# PIC16F722A register map
Vendor: Microchip
Architecture 16xxxx. Special function registers and configuration words.
Registers are 8-bit, read-write, reset 0x0 unless marked. A register's access mark holds for its fields unless they carry their own. Addresses are absolute, and some are shared; only a register's first bit layout is shown; lines under a group give offsets from that group; [hi:lo] are bit positions; {n}, {i} and the like mark numbered series; 'fields as' and 'values as' point back to an identical list; <NAME> marks a mode.

## Further device data
pins=1: RE3/MCLR/Vpp; 2: RA0/AN0/SS/Vcap; 3: RA1/AN1; 4: RA2/AN2; 5: RA3/AN3/Vref; 6: RA4/CPS6/T0CKI; 7: RA5/AN4/CPS7/SS/Vcap; 8: Vss; 9: RA7/OSC1/CLKIN; 10: RA6/OSC2/CLKOUT/Vcap; 11: RC0/T1OSO/T1CKI; 12: RC1/T1OSI/CCP2; 13: RC2/CCP1; 14: RC3/SCK/SCL; 15: RC4/SDI/SDA; 16: RC5/SDO; 17: RC6/TX/CK; 18: RC7/RX/DT; 19: Vss; 20: Vdd; 21: RB0/AN12/CPS0/INT; 22: RB1/AN10/CPS1; 23: RB2/AN8/CPS2; 24: RB3/AN9/CPS3/CCP2; 25: RB4/AN11/CPS4; 26: RB5/AN13/CPS5/T1G; 27: RB6/ICSPCLK/ICDCLK; 28: RB7/ICSPDAT/ICDDAT

## SFR
0x00 INDF access not given
0x01 TMR0 reset not defined — (power-on value xxxxxxxx)
0x02 PCL
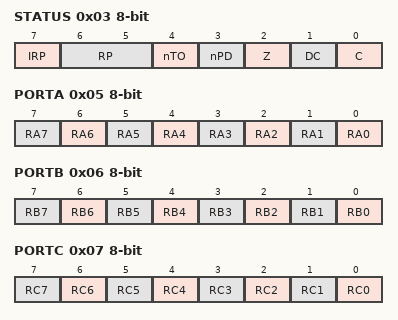
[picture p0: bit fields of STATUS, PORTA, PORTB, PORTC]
0x03 STATUS reset not defined — (power-on value 00011xxx)
  [7] IRP, [6:5] RP, [4] nTO ro, [3] nPD ro, [2] Z, [1] DC, [0] C
0x04 FSR reset not defined — (power-on value xxxxxxxx)
0x05 PORTA
  [n] RA{n} (n=0..7)
0x06 PORTB reset not defined — (power-on value xxxxxxxx)
  [n] RB{n} (n=0..7)
0x07 PORTC reset not defined — (power-on value xxxxxxxx)
  [n] RC{n} (n=0..7)
0x09 PORTE ro reset not defined — (power-on value ----x---)
  [3] RE3
0x0A PCLATH
  [4:0] PCLATH
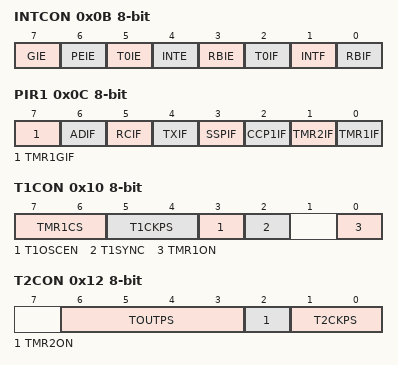
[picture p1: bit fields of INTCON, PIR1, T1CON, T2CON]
0x0B INTCON reset not defined — (power-on value 0000000x)
  [7] GIE, [6] PEIE, [5] T0IE, [4] INTE, [3] RBIE, [2] T0IF, [1] INTF, [0] RBIF
0x0C PIR1
  [7] TMR1GIF, [6] ADIF, [5] RCIF ro, [4] TXIF ro, [3] SSPIF, [2] CCP1IF, [1] TMR2IF, [0] TMR1IF
0x0D PIR2
  [0] CCP2IF
0x0E TMR1L reset not defined — (power-on value xxxxxxxx)
0x0F TMR1H reset not defined — (power-on value xxxxxxxx)
0x10 T1CON
  [7:6] TMR1CS, [5:4] T1CKPS, [3] T1OSCEN, [2] T1SYNC, [0] TMR1ON
0x11 TMR2
0x12 T2CON
  [6:3] TOUTPS, [2] TMR2ON, [1:0] T2CKPS
0x13 SSPBUF reset not defined — (power-on value xxxxxxxx)
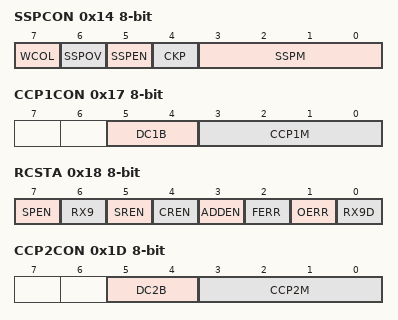
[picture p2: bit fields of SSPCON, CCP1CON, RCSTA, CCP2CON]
0x14 SSPCON
  [7] WCOL, [6] SSPOV, [5] SSPEN, [4] CKP, [3:0] SSPM
0x15 CCPR1L reset not defined — (power-on value xxxxxxxx)
0x16 CCPR1H reset not defined — (power-on value xxxxxxxx)
0x17 CCP1CON
  [5:4] DC1B, [3:0] CCP1M
0x18 RCSTA reset not defined — (power-on value 0000000x)
  [7] SPEN, [6] RX9, [5] SREN, [4] CREN, [3] ADDEN, [2] FERR ro, [1] OERR ro, [0] RX9D ro
0x19 TXREG
0x1A RCREG ro
0x1B CCPR2L reset not defined — (power-on value xxxxxxxx)
0x1C CCPR2H reset not defined — (power-on value xxxxxxxx)
0x1D CCP2CON
  [5:4] DC2B, [3:0] CCP2M
0x1E ADRES reset not defined — (power-on value xxxxxxxx)
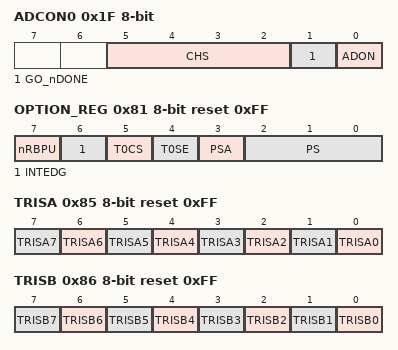
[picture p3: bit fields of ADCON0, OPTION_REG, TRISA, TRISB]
0x1F ADCON0
  [5:2] CHS, [1] GO_nDONE, [0] ADON
0x81 OPTION_REG reset 0xFF
  [7] nRBPU, [6] INTEDG, [5] T0CS, [4] T0SE, [3] PSA, [2:0] PS
0x85 TRISA reset 0xFF
  [n] TRISA{n} (n=0..7)
0x86 TRISB reset 0xFF
  [n] TRISB{n} (n=0..7)
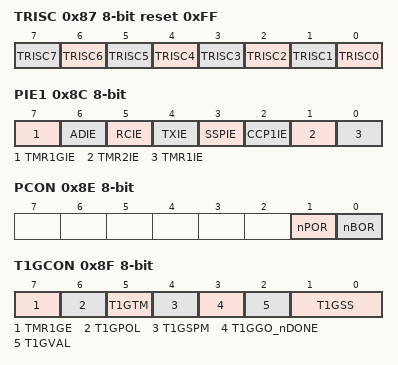
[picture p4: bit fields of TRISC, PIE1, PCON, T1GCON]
0x87 TRISC reset 0xFF
  [n] TRISC{n} (n=0..7)
0x89 TRISE ro reset 0x8
  [3] TRISE3
0x8C PIE1
  [7] TMR1GIE, [6] ADIE, [5] RCIE, [4] TXIE, [3] SSPIE, [2] CCP1IE, [1] TMR2IE, [0] TMR1IE
0x8D PIE2
  [0] CCP2IE
0x8E PCON reset not defined — (power-on value ------qq)
  [1] nPOR, [0] nBOR
0x8F T1GCON
  [7] TMR1GE, [6] T1GPOL, [5] T1GTM, [4] T1GSPM, [3] T1GGO_nDONE, [2] T1GVAL ro, [1:0] T1GSS
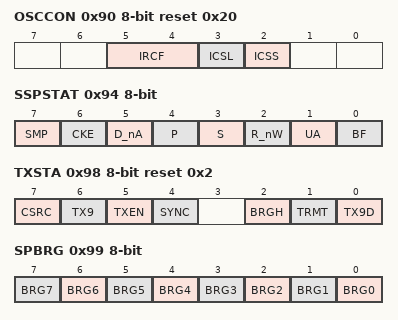
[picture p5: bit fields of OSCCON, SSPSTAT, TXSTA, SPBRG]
0x90 OSCCON reset 0x20
  [5:4] IRCF, [3] ICSL, [2] ICSS
0x91 OSCTUNE
  [5:0] TUN
0x92 PR2 reset 0xFF
0x93 SSPADD
0x93 SSPMSK reset 0xFF
0x94 SSPSTAT
  [7] SMP, [6] CKE, [5] D_nA, [4] P, [3] S, [2] R_nW, [1] UA, [0] BF
0x95 WPUB reset 0xFF
0x96 IOCB
0x98 TXSTA reset 0x2
  [7] CSRC, [6] TX9, [5] TXEN, [4] SYNC, [2] BRGH, [1] TRMT ro, [0] TX9D
0x99 SPBRG
  [n] BRG{n} (n=0..7)
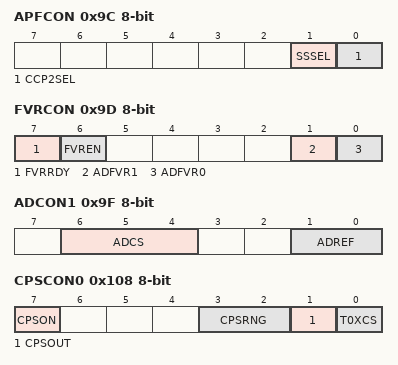
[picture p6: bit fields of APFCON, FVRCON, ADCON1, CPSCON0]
0x9C APFCON
  [1] SSSEL, [0] CCP2SEL
0x9D FVRCON reset not defined — (power-on value x0----00)
  [7] FVRRDY ro, [6] FVREN, [1] ADFVR1, [0] ADFVR0
0x9F ADCON1
  [6:4] ADCS, [1:0] ADREF
0x108 CPSCON0
  [7] CPSON, [3:2] CPSRNG, [1] CPSOUT ro, [0] T0XCS
0x109 CPSCON1
  [3:0] CPSCH
0x10C PMDATL reset not defined — (power-on value xxxxxxxx)
0x10D PMADRL reset not defined — (power-on value xxxxxxxx)
0x10E PMDATH reset not defined — (power-on value --xxxxxx)
  [5:0] PMDATH
0x10F PMADRH reset not defined — (power-on value ---xxxxx)
  [4:0] PMADRH
0x185 ANSELA reset 0x3F
  [5:0] ANSA
0x186 ANSELB reset 0x3F
  [5:0] ANSB
0x18C PMCON1 reset 0x80
  [0] RD

## CONFIG — Configuration words, addresses in ProgramSpace
0x2007 CONFIG1 14-bit reset 0x3FFF
  [13] DEBUG — In-Circuit Debugger Mode bit
    1=OFF (In-circuit debugger disabled, RB6/ICSPCLK and RB7/ICSPDAT are general purpose I/O pins); 0=ON (In-circuit debugger enabled, RB6/ICSPCLK and RB7/ICSPDAT are dedicated to the debugger)
  [12] PLLEN — INTOSC PLL Enable bit
    1=ON (INTOSC Frequency is 16MHz (32x)); 0=OFF (INTOSC Frequency is 500 kHz)
  [10] BORV — Brown-out Reset Voltage selection bit
    1=Brown-out Reset Voltage (VBOR) set to 1.9 V nominal; 0=Brown-out Reset Voltage (VBOR) set to 2.5 V nominal
  [9:8] BOREN — Brown-out Reset Selection bits
    3=ON (BOR enabled); 2=NSLEEP (BOR enabled during operation and disabled in Sleep); 0=OFF (BOR disabled)
  [6] CP — Code Protection bit
    1=OFF (Program memory code protection is disabled); 0=ON (Program memory code protection is enabled)
  [5] MCLRE — RE3/MCLR Pin Function Select bit
    0=OFF (RE3/MCLR pin function is digital input, MCLR internally tied to VDD); 1=ON (RE3/MCLR pin function is MCLR)
  [4] PWRTE — Power-up Timer Enable bit
    1=OFF (PWRT disabled); 0=ON (PWRT enabled)
  [3] WDTE — Watchdog Timer Enable bit
    1=ON (WDT enabled); 0=OFF (WDT disabled and can be enabled by SWDTEN bit of the WDTCON register)
  [2:0] FOSC — Oscillator Selection bits
    7=EXTRCCLK (RC oscillator: CLKOUT function on RA6/OSC2/CLKOUT pin, RC on RA7/OSC1/CLKIN); 6=EXTRCIO (RCIO oscillator: I/O function on RA6/OSC2/CLKOUT pin, RC on RA7/OSC1/CLKIN); 5=INTOSCCLK (INTOSC oscillator: CLKOUT function on RA6/OSC2/CLKOUT pin, I/O function on RA7/OSC1/CLKIN); 4=INTOSCIO (INTOSCIO oscillator: I/O function on RA6/OSC2/CLKOUT pin, I/O function on RA7/OSC1/CLKIN); 3=EC (EC: I/O function on RA6/OSC2/CLKOUT pin, CLKIN on RA7/OSC1/CLKIN); 2=HS (HS oscillator: High-speed crystal/resonator on RA6/OSC2/CLKOUT and RA7/OSC1/CLKIN); 1=XT (XT oscillator: Crystal/resonator on RA6/OSC2/CLKOUT and RA7/OSC1/CLKIN); 0=LP (LP oscillator: Low-power crystal on RA6/OSC2/CLKOUT and RA7/OSC1/CLKIN)
0x2008 CONFIG2 reset 0xFFFF
  [5:4] VCAPEN — Voltage Regulator Capacitor Enable bits
    3=DIS (All VCAP pin functions are disabled); 2=RA6 (VCAP functionality is enabled on RA6); 1=RA5 (VCAP functionality is enabled on RA5); 0=RA0 (VCAP functionality is enabled on RA0)
